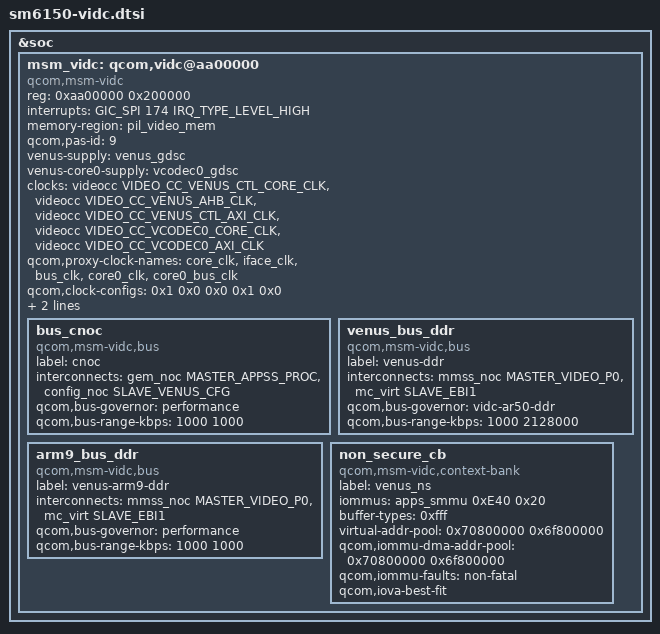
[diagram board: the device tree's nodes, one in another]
/*
 * Venus (AR50, VPU 4) video codec of sm6150 for the forward-ported 4.14
 * msm_vidc driver (techpack/video). Values are from the 4.14 sm6150-vidc.dtsi
 * and were checked against the live /sys/firmware/devicetree of violet.
 *
 * Differences from 4.14:
 *  - memory-region: the firmware carveout is loaded by the driver itself
 *    (qcom_mdt_load + PAS 9) instead of the PIL node qcom,venus@aae0000.
 *  - interconnects: the msm_bus master/slave pairs are interconnect paths.
 *  - the IOVA pool of a context bank is qcom,iommu-dma-addr-pool, read by
 *    the IOMMU core; virtual-addr-pool stays for the driver's own checks.
 *  - no cx-ipeak.
 *  - the three secure context banks are left out for now: programming a
 *    secure VMID goes through TZ (see violet-sm6150-sde.dtsi).
 */

#include <dt-bindings/interrupt-controller/arm-gic.h>
#include <dt-bindings/interconnect/qcom,icc.h>
#include <dt-bindings/interconnect/qcom,sm6150.h>
#include <dt-bindings/clock/qcom,videocc-sm6150.h>

&soc {
	msm_vidc: qcom,vidc@aa00000 {
		compatible = "qcom,msm-vidc", "qcom,sm6150-vidc";
		status = "okay";
		reg = <0xaa00000 0x200000>;
		interrupts = <GIC_SPI 174 IRQ_TYPE_LEVEL_HIGH>;
		memory-region = <&pil_video_mem>;
		qcom,pas-id = <9>;

		/* Supply */
		venus-supply = <&venus_gdsc>;
		venus-core0-supply = <&vcodec0_gdsc>;

		/* Clocks */
		clock-names = "core_clk", "iface_clk", "bus_clk",
			"core0_clk", "core0_bus_clk";
		clocks = <&videocc VIDEO_CC_VENUS_CTL_CORE_CLK>,
			<&videocc VIDEO_CC_VENUS_AHB_CLK>,
			<&videocc VIDEO_CC_VENUS_CTL_AXI_CLK>,
			<&videocc VIDEO_CC_VCODEC0_CORE_CLK>,
			<&videocc VIDEO_CC_VCODEC0_AXI_CLK>;
		qcom,proxy-clock-names = "core_clk", "iface_clk",
			"bus_clk", "core0_clk", "core0_bus_clk";
		qcom,clock-configs = <0x1 0x0 0x0 0x1 0x0>;
		qcom,allowed-clock-rates = <133330000 240000000 300000000
			380000000 410000000>;

		/* Buses */
		bus_cnoc {
			compatible = "qcom,msm-vidc,bus";
			label = "cnoc";
			interconnects = <&gem_noc MASTER_APPSS_PROC
					 &config_noc SLAVE_VENUS_CFG>;
			qcom,bus-governor = "performance";
			qcom,bus-range-kbps = <1000 1000>;
		};

		venus_bus_ddr {
			compatible = "qcom,msm-vidc,bus";
			label = "venus-ddr";
			interconnects = <&mmss_noc MASTER_VIDEO_P0
					 &mc_virt SLAVE_EBI1>;
			qcom,bus-governor = "vidc-ar50-ddr";
			qcom,bus-range-kbps = <1000 2128000>;
		};

		arm9_bus_ddr {
			compatible = "qcom,msm-vidc,bus";
			label = "venus-arm9-ddr";
			interconnects = <&mmss_noc MASTER_VIDEO_P0
					 &mc_virt SLAVE_EBI1>;
			qcom,bus-governor = "performance";
			qcom,bus-range-kbps = <1000 1000>;
		};

		/* MMUs */
		non_secure_cb {
			compatible = "qcom,msm-vidc,context-bank";
			label = "venus_ns";
			iommus = <&apps_smmu 0xE40 0x20>;
			buffer-types = <0xfff>;
			virtual-addr-pool = <0x70800000 0x6f800000>;
			qcom,iommu-dma-addr-pool = <0x70800000 0x6f800000>;
			qcom,iommu-faults = "non-fatal";
			qcom,iova-best-fit;
		};
	};
};
